# GD32H71x_72x register map
File version: 1.0
CPU: CM7 r1p2, little endian, MPU, FPU, 4 interrupt priority bits
Registers are 32-bit, read-write, reset 0x0 unless marked. A register's access mark holds for its fields unless they carry their own. Offsets are from the block's base; [hi:lo] are bit positions; {n}, {i} and the like mark numbered series.

## NVIC — Nested Vectored Interrupt Controller
Base 0xE000E100
{0x0+4i} ISER{i} (i=0..2) — Interrupt Set-Enable Register
  [31:0] SETENA
0x0C ISER3 — Interrupt Set-Enable Register
{0x80+4i} ICER{i} (i=0..2) — Interrupt Clear-Enable Register
  [31:0] CLRENA
0x8C ICER3 — Interrupt Clear-Enable Register
{0x100+4i} ISPR{i} (i=0..2) — Interrupt Set-Pending Register
  [31:0] SETPEND
0x10C ISPR3 — Interrupt Set-Pending Register
{0x180+4i} ICPR{i} (i=0..2) — Interrupt Clear-Pending Register
  [31:0] CLRPEND
0x1C0 ICPR3 — Interrupt Clear-Pending Register
{0x200+4i} IABR{i} ro (i=0..2) — Interrupt Active Bit Register
  [31:0] ACTIVE
0x20C IABR3 — Interrupt Active Bit Register
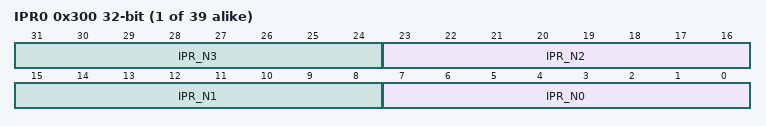
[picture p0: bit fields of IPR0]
{0x300+4i} IPR{i} (i=0..38) — Interrupt Priority Register
  [8n+7:8n] IPR_N{n} (n=0..3)

## PKCAU — Public Key Cryptographic Acceleration Unit
Base 0x48000000
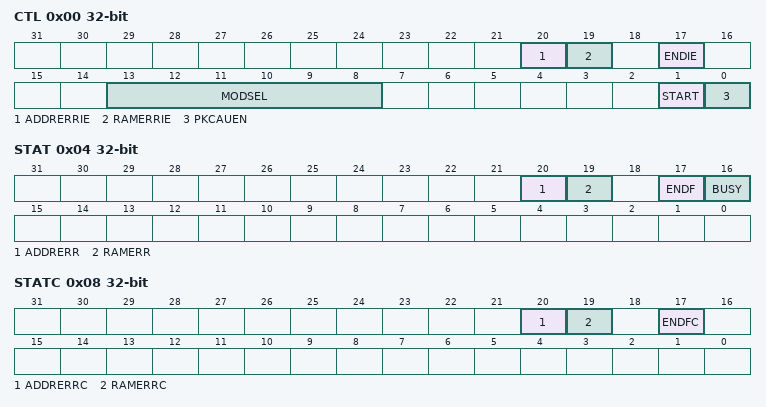
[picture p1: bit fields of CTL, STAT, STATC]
0x00 CTL — Control register
  [20] ADDRERRIE — Address error interrupt enable
  [19] RAMERRIE — RAM error interrupt enable
  [17] ENDIE — End of operation interrupt enable
  [13:8] MODSEL — PKCAU operation mode selection
  [1] START — PKCAU starts operation
  [0] PKCAUEN — PKCAU enable
0x04 STAT ro — Status register
  [20] ADDRERR — Address error.
  [19] RAMERR — PKCAU RAM error
  [17] ENDF — End of PKCAU operation
  [16] BUSY — Busy flag
0x08 STATC wo — Status clear register
  [20] ADDRERRC — Address error flag clear.
  [19] RAMERRC — PKCAU RAM error flag clear.
  [17] ENDFC — End of PKCAU operation flag clear.

## RAMECCMU0 — RAM ECC monitor unit0
Base 0x52009000
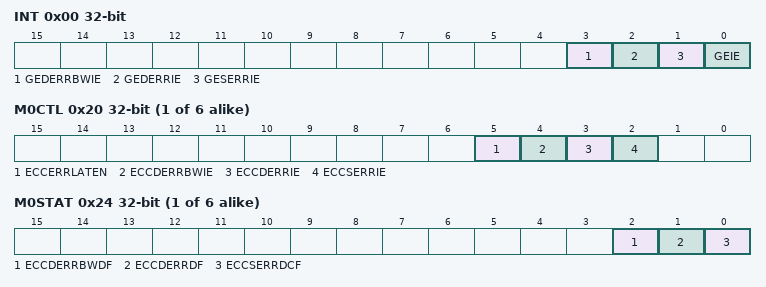
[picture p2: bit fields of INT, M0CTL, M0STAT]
0x00 INT — RAMECCMU global interrupt register
  [3] GEDERRBWIE — Global ECC double bits error on byte write interrupt enable
  [2] GEDERRIE — Global ECC double bits error interrupt enable
  [1] GESERRIE — Global ECC single bit error interrupt enable
  [0] GEIE — Global ECC interrupt enable
{0x20+0x20*i} M{i}CTL (i=0..5) — RAMECCMU monitor {i} control regist
  [5] ECCERRLATEN — ECC error latching enable
  [4] ECCDERRBWIE — ECC double bits error on byte write interrupt enable
  [3] ECCDERRIE — ECC double bits error interrupt enable
  [2] ECCSERRIE — ECC single bit error interrupt enable
{0x24+0x20*i} M{i}STAT (i=0..5) — RAMECCMU monitor {i} status regist
  [2] ECCDERRBWDF — ECC double bits error on byte write detected flag
  [1] ECCDERRDF — ECC double bits error detected flag
  [0] ECCSERRDCF — ECC single bit error detected and corrected flag
{0x28+0x20*i} M{i}FADDR ro (i=0..5) — RAMECCMU monitor {i} failing address regist
  [31:0] ECCFADDR — ECC error failing address
{0x2C+0x20*i} M{i}FDL ro (i=0..5) — RAMECCMU monitor {i} failing data low regist
  [31:0] ECCFDL — ECC failing data low bits
{0x30+0x20*i} M{i}FDH ro (i=0..5) — RAMECCMU monitor {i} failing data high regist
  [31:0] ECCFDH — ECC failing data high bits (64-bit)
{0x34+0x20*i} M{i}FECODE ro (i=0..5) — RAMECCMU monitor {i} failing ECC error code regist
  [31:0] ECCFECODE — ECC failing error code

## RAMECCMU1 — RAM ECC monitor unit 1
Base 0x48023000
Registers as RAMECCMU0, without M{n}CTL (n=3..5), M{n}STAT (n=3..5), M{n}FADDR (n=3..5), M{n}FDL (n=3..5), M{n}FDH (n=3..5), M{n}FECODE (n=3..5).

## RTDEC — Real-time decryption
Base 0x5200B800
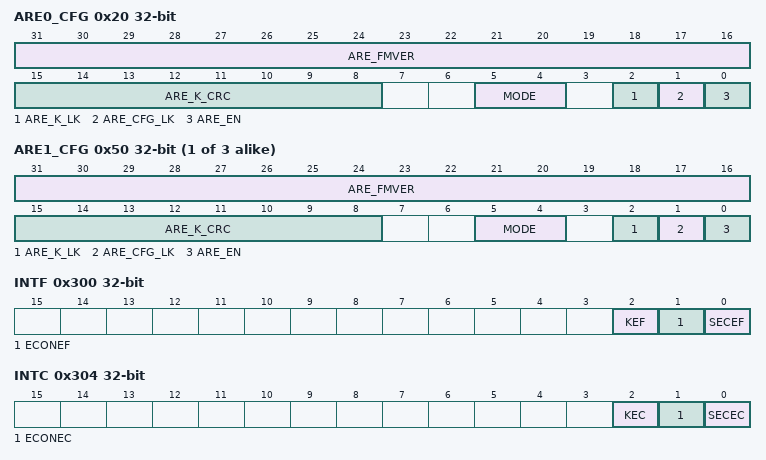
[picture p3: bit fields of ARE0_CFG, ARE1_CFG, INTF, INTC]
0x20 ARE0_CFG access per field — Area 0 configuration regist
  [31:16] ARE_FMVER rw — Area firmware version bits
  [15:8] ARE_K_CRC ro — 8-bit CRC of area key bits
  [5:4] MODE rw — RTDEC mode bits
  [2] ARE_K_LK ro — Area key lock bit
  [1] ARE_CFG_LK ro — Area configure lock bit
  [0] ARE_EN rw — Area real-time decryption enable bit
{0x24+0x30*i} ARE{i}_SADDR (i=0..3) — Area {i} start address regist
  [31:0] ARE_SADDR — Area x start address bits
{0x28+0x30*i} ARE{i}_EADDR reset 0xFFFF (i=0..3) — Area {i} end address regist
  [31:0] ARE_EADDR — Area x end address bits
0x2C ARE0_NONCE0 — Area 0 nonce 0 register 0
  [31:0] ARE_NONCE0 — Area 0 nonce address bits
0x30 ARE0_NONCE1 — Area 0 nonce register 1
  [31:0] ARE_NONCE1 — Area 0 nonce 1 address bits
{0x34+0x30*i} ARE{i}_KEY0 wo (i=0..3) — Area {i} key register
  [31:0] ARE_KEY0 — Area x key bits, ARE_KEY[31:0]
{0x38+0x30*i} ARE{i}_KEY1 wo (i=0..3) — Area {i} key register
  [31:0] ARE_KEY1 — Area x key bits, ARE_KEY[63:32]
{0x3C+0x30*i} ARE{i}_KEY2 wo (i=0..3) — Area {i} key register
  [31:0] ARE_KEY2 — Area x key bits, ARE_KEY[95:64]
{0x40+0x30*i} ARE{i}_KEY3 ro (i=0..3) — Area {i} key register
  [31:0] ARE_KEY3 — Area x key bits, ARE_KEY[127:96]
{0x20+0x30*i} ARE{i}_CFG access per field (i=1..3) — Area {i} configuration regist
  [31:16] ARE_FMVER rw — Area firmware version bits
  [15:8] ARE_K_CRC rw — 8-bit CRC of area key bits
  [5:4] MODE rw — RTDEC mode bits
  [2] ARE_K_LK ro — Area key lock bit
  [1] ARE_CFG_LK ro — Area configure lock bit
  [0] ARE_EN rw — Area real-time decryption enable bit
{0x2C+0x30*i} ARE{i}_NONCE0 (i=1..3) — Area {i} nonce register 0
  [31:0] ARE_NONCE0 — Area {i} nonce 0 address bits
0x60 ARE1_NONCE1 — Area 1 nonce register 1
  [31:0] ARE_NONCE1 — Area 1 nonce 1 address bits, ARE_RANDNUM[63:32]
0x90 ARE2_NONCE1 — Area 2 nonce register 1
  [31:0] ARE_NONCE1 — Area 2 nonce 1 address bits, ARE_RANDNUM[63:32]
0xC0 ARE3_NONCE1 — Area 3 nonce register
  [31:0] ARE_NONCE1 — Area 3 nonce 1 address bits, ARE_RANDNUM[63:32]
0x300 INTF ro — Interrupt flag register
  [2] KEF — Key error interrupt flag
  [1] ECONEF — Execute-only or execute-never error interrupt flag
  [0] SECEF — Security error interrupt flag
0x304 INTC wo — Interrupt flag clear register
  [2] KEC — Key error flag clear
  [1] ECONEC — Execute-only or execute-never error flag clear
  [0] SECEC — Security error interrupt flag
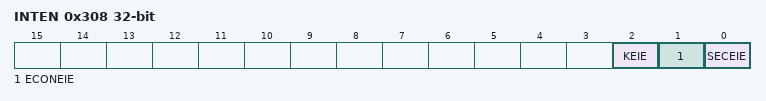
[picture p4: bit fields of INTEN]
0x308 INTEN — Interrupt enable register
  [2] KEIE — Enable bit for key error interrupt
  [1] ECONEIE — Enable bit for execute-only or execute-never error interrupt
  [0] SECEIE — Enable bit for security error interrupt
